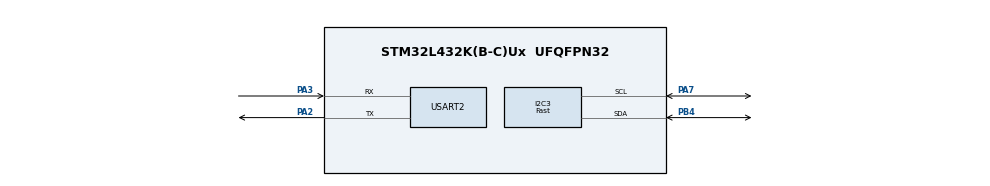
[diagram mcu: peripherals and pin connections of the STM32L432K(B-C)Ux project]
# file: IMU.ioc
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FREERTOS.BinarySemaphores01=TimerSem,Dynamic,NULL
FREERTOS.Queues01=IMUqueue,16,uint16_t,NULL,Dynamic,NULL,NULL
FREERTOS.Tasks01=IMUtask,0,128,startIMUtask,Default,NULL,Dynamic,NULL,NULL
I2C3.I2C_Speed_Mode=I2C_Fast
I2C3.Speed=296
I2C3.Timing=0x00000007
Mcu.Family=STM32L4
Mcu.Name=STM32L432K(B-C)Ux
Mcu.Package=UFQFPN32
NVIC.PriorityGroup=NVIC_PRIORITYGROUP_4
NVIC.TIM1_BRK_TIM15_IRQn=true\:5\:0\:false\:false\:true\:true\:true
NVIC.TIM1_CC_IRQn=true\:5\:0\:false\:false\:true\:true\:true
NVIC.TIM1_TRG_COM_IRQn=true\:5\:0\:false\:false\:true\:true\:true
NVIC.TIM1_UP_TIM16_IRQn=true\:5\:0\:false\:false\:true\:true\:true
NVIC.TIM2_IRQn=true\:0\:0\:false\:false\:true\:false\:false
NVIC.TimeBase=TIM2_IRQn
NVIC.TimeBaseIP=TIM2
NVIC.USART2_IRQn=true\:5\:0\:false\:false\:true\:true\:true
PA2.Mode=Asynchronous
PA2.Signal=USART2_TX
PA3.Mode=Asynchronous
PA3.Signal=USART2_RX
PA7.Mode=I2C
PA7.Signal=I2C3_SCL
PB4\ (NJTRST).Mode=I2C
PB4\ (NJTRST).Signal=I2C3_SDA
ProjectManager.HeapSize=0x200
ProjectManager.StackSize=0x400
ProjectManager.TargetToolchain=SW4STM32
RCC.HSE_VALUE=8000000
RCC.HSI48_VALUE=48000000
RCC.HSI_VALUE=16000000
RCC.LSE_VALUE=32768
RCC.MSI_VALUE=4000000
RCC.VCOOutputFreq_Value=32000000
TIM1.Period=9
TIM1.Prescaler=399
USART2.VirtualMode-Asynchronous=VM_ASYNC
USART2.WordLength=WORDLENGTH_8B
VP_FREERTOS_VS_ENABLE.Mode=Enabled
VP_SYS_VS_tim2.Mode=TIM2
VP_TIM1_VS_ClockSourceINT.Mode=Internal
board=IMU

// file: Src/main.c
/**
  ******************************************************************************
  * File Name          : main.c
  * Description        : Main program body
  ******************************************************************************
  * This notice applies to any and all portions of this file
  * that are not between comment pairs USER CODE BEGIN and
  * USER CODE END. Other portions of this file, whether
  * inserted by the user or by software development tools
  * are owned by their respective copyright owners.
  *
  * Copyright (c) 2017 STMicroelectronics International N.V.
  * All rights reserved.
  *
  * Redistribution and use in source and binary forms, with or without
  * modification, are permitted, provided that the following conditions are met:
  *
  * 1. Redistribution of source code must retain the above copyright notice,
  *    this list of conditions and the following disclaimer.
  * 2. Redistributions in binary form must reproduce the above copyright notice,
  *    this list of conditions and the following disclaimer in the documentation
  *    and/or other materials provided with the distribution.
  * 3. Neither the name of STMicroelectronics nor the names of other
  *    contributors to this software may be used to endorse or promote products
  *    derived from this software without specific written permission.
  * 4. This software, including modifications and/or derivative works of this
  *    software, must execute solely and exclusively on microcontroller or
  *    microprocessor devices manufactured by or for STMicroelectronics.
  * 5. Redistribution and use of this software other than as permitted under
  *    this license is void and will automatically terminate your rights under
  *    this license.
  *
  * THIS SOFTWARE IS PROVIDED BY STMICROELECTRONICS AND CONTRIBUTORS "AS IS"
  * AND ANY EXPRESS, IMPLIED OR STATUTORY WARRANTIES, INCLUDING, BUT NOT
  * LIMITED TO, THE IMPLIED WARRANTIES OF MERCHANTABILITY, FITNESS FOR A
  * PARTICULAR PURPOSE AND NON-INFRINGEMENT OF THIRD PARTY INTELLECTUAL PROPERTY
  * RIGHTS ARE DISCLAIMED TO THE FULLEST EXTENT PERMITTED BY LAW. IN NO EVENT
  * SHALL STMICROELECTRONICS OR CONTRIBUTORS BE LIABLE FOR ANY DIRECT, INDIRECT,
  * INCIDENTAL, SPECIAL, EXEMPLARY, OR CONSEQUENTIAL DAMAGES (INCLUDING, BUT NOT
  * LIMITED TO, PROCUREMENT OF SUBSTITUTE GOODS OR SERVICES; LOSS OF USE, DATA,
  * OR PROFITS; OR BUSINESS INTERRUPTION) HOWEVER CAUSED AND ON ANY THEORY OF
  * LIABILITY, WHETHER IN CONTRACT, STRICT LIABILITY, OR TORT (INCLUDING
  * NEGLIGENCE OR OTHERWISE) ARISING IN ANY WAY OUT OF THE USE OF THIS SOFTWARE,
  * EVEN IF ADVISED OF THE POSSIBILITY OF SUCH DAMAGE.
  *
  ******************************************************************************
  */

#include "main.h"
#include "stm32l4xx_hal.h"
#include "cmsis_os.h"
#include "i2c.h"
#include "tim.h"
#include "usart.h"
#include "gpio.h"

/* USER CODE BEGIN Includes */
#include "MPU6050.h"
/* USER CODE END Includes */

/* USER CODE BEGIN PV */
/* Private variables ---------------------------------------------------------*/
MPU6050_HandleTypeDef global_MPU6050_struct;
/* USER CODE END PV */

void SystemClock_Config(void);
void MX_FREERTOS_Init(void);

/* USER CODE BEGIN PFP */
/* Private function prototypes -----------------------------------------------*/

/* USER CODE END PFP */

int main(void)
{

  /* MCU Configuration----------------------------------------------------------*/

  /* Reset of all peripherals, Initializes the Flash interface and the Systick. */
  HAL_Init();

  /* Configure the system clock */
  SystemClock_Config();

  /* Initialize all configured peripherals */
  MX_GPIO_Init();
  MX_USART2_UART_Init();
  MX_I2C3_Init();
  MX_TIM1_Init();

  /* Call init function for freertos objects (in freertos.c) */
  MX_FREERTOS_Init();

  /* Start scheduler */
  osKernelStart();

  /* We should never get here as control is now taken by the scheduler */

  /* Infinite loop */
  while (1)
  {

  }

}

/** System Clock Configuration
*/
void SystemClock_Config(void)
{

  RCC_OscInitTypeDef RCC_OscInitStruct;
  RCC_ClkInitTypeDef RCC_ClkInitStruct;
  RCC_PeriphCLKInitTypeDef PeriphClkInit;

    /**Initializes the CPU, AHB and APB busses clocks
    */
  RCC_OscInitStruct.OscillatorType = RCC_OSCILLATORTYPE_MSI;
  RCC_OscInitStruct.MSIState = RCC_MSI_ON;
  RCC_OscInitStruct.MSICalibrationValue = 0;
  RCC_OscInitStruct.MSIClockRange = RCC_MSIRANGE_6;
  RCC_OscInitStruct.PLL.PLLState = RCC_PLL_NONE;
  if (HAL_RCC_OscConfig(&RCC_OscInitStruct) != HAL_OK)
  {
    _Error_Handler(__FILE__, __LINE__);
  }

    /**Initializes the CPU, AHB and APB busses clocks
    */
  RCC_ClkInitStruct.ClockType = RCC_CLOCKTYPE_HCLK|RCC_CLOCKTYPE_SYSCLK
                              |RCC_CLOCKTYPE_PCLK1|RCC_CLOCKTYPE_PCLK2;
  RCC_ClkInitStruct.SYSCLKSource = RCC_SYSCLKSOURCE_MSI;
  RCC_ClkInitStruct.AHBCLKDivider = RCC_SYSCLK_DIV1;
  RCC_ClkInitStruct.APB1CLKDivider = RCC_HCLK_DIV1;
  RCC_ClkInitStruct.APB2CLKDivider = RCC_HCLK_DIV1;

  if (HAL_RCC_ClockConfig(&RCC_ClkInitStruct, FLASH_LATENCY_0) != HAL_OK)
  {
    _Error_Handler(__FILE__, __LINE__);
  }

  PeriphClkInit.PeriphClockSelection = RCC_PERIPHCLK_USART2|RCC_PERIPHCLK_I2C3;
  PeriphClkInit.Usart2ClockSelection = RCC_USART2CLKSOURCE_PCLK1;
  PeriphClkInit.I2c3ClockSelection = RCC_I2C3CLKSOURCE_PCLK1;
  if (HAL_RCCEx_PeriphCLKConfig(&PeriphClkInit) != HAL_OK)
  {
    _Error_Handler(__FILE__, __LINE__);
  }

    /**Configure the main internal regulator output voltage
    */
  if (HAL_PWREx_ControlVoltageScaling(PWR_REGULATOR_VOLTAGE_SCALE1) != HAL_OK)
  {
    _Error_Handler(__FILE__, __LINE__);
  }

    /**Configure the Systick interrupt time
    */
  HAL_SYSTICK_Config(HAL_RCC_GetHCLKFreq()/1000);

    /**Configure the Systick
    */
  HAL_SYSTICK_CLKSourceConfig(SYSTICK_CLKSOURCE_HCLK);

  /* SysTick_IRQn interrupt configuration */
  HAL_NVIC_SetPriority(SysTick_IRQn, 15, 0);
}

void HAL_TIM_PeriodElapsedCallback(TIM_HandleTypeDef *htim)
{
  if (htim->Instance == TIM2) {
    HAL_IncTick();
  }
}

void _Error_Handler(char * file, int line)
{
  while(1)
  {
  }
}

/************************ (C) COPYRIGHT STMicroelectronics *****END OF FILE****/
